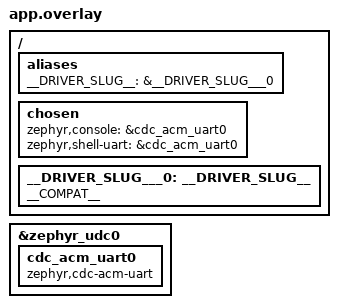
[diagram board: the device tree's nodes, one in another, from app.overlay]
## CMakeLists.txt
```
cmake_minimum_required(VERSION 3.20.0)

set(BOARD rpi_pico2/rp2350a/m33)
set(BOARD_FLASH_RUNNER uf2)
list(APPEND ZEPHYR_EXTRA_MODULES ${CMAKE_CURRENT_SOURCE_DIR}/../..)

find_package(Zephyr REQUIRED HINTS $ENV{ZEPHYR_BASE})
project(__DRIVER_SLUG___repl)

target_sources(app PRIVATE src/main.c)
```

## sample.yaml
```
sample:
  name: __DRIVER_UPPER__ REPL
common:
  tags: drivers
  platform_allow:
    - rpi_pico2/rp2350a/m33
  build_only: true
tests:
  sample.__DRIVER_SLUG__.repl: {}
```

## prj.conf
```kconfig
CONFIG_SHELL=y
CONFIG_SERIAL=y
CONFIG_CONSOLE=y
CONFIG_UART_CONSOLE=y
CONFIG_SHELL_BACKEND_SERIAL=y
CONFIG_UART_LINE_CTRL=y
CONFIG_LOG=y
CONFIG_CBPRINTF_FP_SUPPORT=y
CONFIG_SHELL_STACK_SIZE=4096

CONFIG_USB_DEVICE_STACK_NEXT=y
CONFIG_CDC_ACM_SERIAL_INITIALIZE_AT_BOOT=y
CONFIG_USBD_CDC_ACM_LOG_LEVEL_OFF=y
CONFIG_USBD_LOG_LEVEL_OFF=y

CONFIG___KCONFIG_SYM__=y
CONFIG___KCONFIG_SYM___BACKEND_PUBLIC_MOCK=y
```

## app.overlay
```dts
/ {
	aliases {
		__DRIVER_SLUG__ = &__DRIVER_SLUG___0;
	};

	chosen {
		zephyr,console = &cdc_acm_uart0;
		zephyr,shell-uart = &cdc_acm_uart0;
	};

	__DRIVER_SLUG___0: __DRIVER_SLUG__ {
		compatible = "__COMPAT__";
		status = "okay";
	};
};

&zephyr_udc0 {
	cdc_acm_uart0: cdc_acm_uart0 {
		compatible = "zephyr,cdc-acm-uart";
	};
};
```

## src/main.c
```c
#include <zephyr/device.h>
#include <zephyr/shell/shell.h>

#include <__DRIVER_SLUG__.h>

static __DRIVER_SLUG___t *sh_dev(const struct shell *sh)
{
	const struct device *zdev = DEVICE_DT_GET(DT_ALIAS(__DRIVER_SLUG__));

	if (!device_is_ready(zdev)) {
		shell_error(sh, "device not ready");
		return NULL;
	}

	return __DRIVER_SLUG___from_dev(zdev);
}

static int cmd_status(const struct shell *sh, size_t argc, char **argv)
{
	__DRIVER_SLUG___t *dev = sh_dev(sh);

	ARG_UNUSED(argc);
	ARG_UNUSED(argv);

	if (dev == NULL) {
		return -ENODEV;
	}

	/* FILL IN: call other public APIs via this same from_dev handle. */
	shell_print(sh, "ready");
	return 0;
}

SHELL_STATIC_SUBCMD_SET_CREATE(__DRIVER_SLUG___cmds,
			       SHELL_CMD(status, NULL, "Check the driver is ready", cmd_status),
			       SHELL_SUBCMD_SET_END);

SHELL_CMD_REGISTER(__DRIVER_SLUG__, &__DRIVER_SLUG___cmds, "__DRIVER_UPPER__ driver", NULL);

int main(void)
{
	return 0;
}
```
